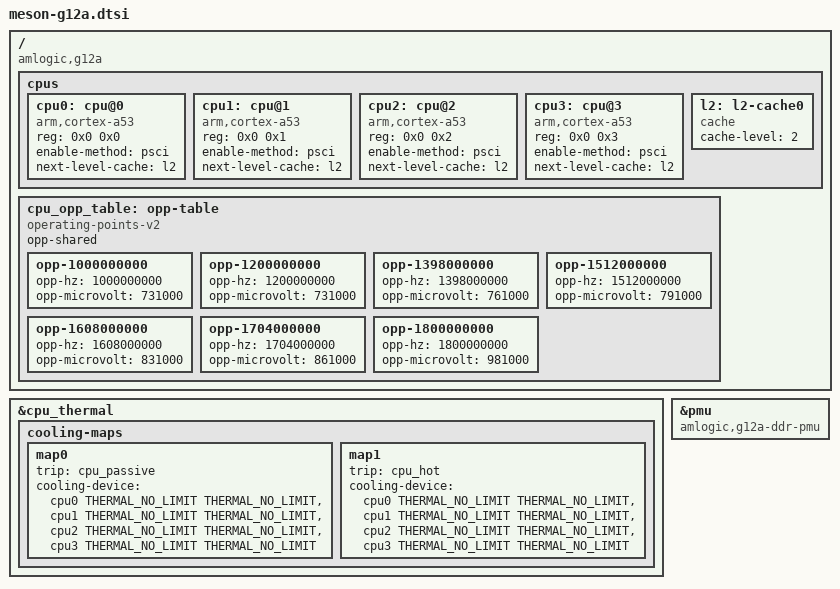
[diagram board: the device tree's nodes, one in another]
// SPDX-License-Identifier: (GPL-2.0+ OR MIT)
/*
 * Copyright (c) 2018 Amlogic, Inc. All rights reserved.
 */

#include "meson-g12.dtsi"

/ {
	compatible = "amlogic,g12a";

	cpus {
		#address-cells = <0x2>;
		#size-cells = <0x0>;

		cpu0: cpu@0 {
			device_type = "cpu";
			compatible = "arm,cortex-a53";
			reg = <0x0 0x0>;
			enable-method = "psci";
			next-level-cache = <&l2>;
			#cooling-cells = <2>;
		};

		cpu1: cpu@1 {
			device_type = "cpu";
			compatible = "arm,cortex-a53";
			reg = <0x0 0x1>;
			enable-method = "psci";
			next-level-cache = <&l2>;
			#cooling-cells = <2>;
		};

		cpu2: cpu@2 {
			device_type = "cpu";
			compatible = "arm,cortex-a53";
			reg = <0x0 0x2>;
			enable-method = "psci";
			next-level-cache = <&l2>;
			#cooling-cells = <2>;
		};

		cpu3: cpu@3 {
			device_type = "cpu";
			compatible = "arm,cortex-a53";
			reg = <0x0 0x3>;
			enable-method = "psci";
			next-level-cache = <&l2>;
			#cooling-cells = <2>;
		};

		l2: l2-cache0 {
			compatible = "cache";
			cache-level = <2>;
		};
	};

	cpu_opp_table: opp-table {
		compatible = "operating-points-v2";
		opp-shared;

		opp-1000000000 {
			opp-hz = /bits/ 64 <1000000000>;
			opp-microvolt = <731000>;
		};

		opp-1200000000 {
			opp-hz = /bits/ 64 <1200000000>;
			opp-microvolt = <731000>;
		};

		opp-1398000000 {
			opp-hz = /bits/ 64 <1398000000>;
			opp-microvolt = <761000>;
		};

		opp-1512000000 {
			opp-hz = /bits/ 64 <1512000000>;
			opp-microvolt = <791000>;
		};

		opp-1608000000 {
			opp-hz = /bits/ 64 <1608000000>;
			opp-microvolt = <831000>;
		};

		opp-1704000000 {
			opp-hz = /bits/ 64 <1704000000>;
			opp-microvolt = <861000>;
		};

		opp-1800000000 {
			opp-hz = /bits/ 64 <1800000000>;
			opp-microvolt = <981000>;
		};
	};
};

&cpu_thermal {
	cooling-maps {
		map0 {
			trip = <&cpu_passive>;
			cooling-device = <&cpu0 THERMAL_NO_LIMIT THERMAL_NO_LIMIT>,
					<&cpu1 THERMAL_NO_LIMIT THERMAL_NO_LIMIT>,
					<&cpu2 THERMAL_NO_LIMIT THERMAL_NO_LIMIT>,
					<&cpu3 THERMAL_NO_LIMIT THERMAL_NO_LIMIT>;
		};

		map1 {
			trip = <&cpu_hot>;
			cooling-device = <&cpu0 THERMAL_NO_LIMIT THERMAL_NO_LIMIT>,
					<&cpu1 THERMAL_NO_LIMIT THERMAL_NO_LIMIT>,
					<&cpu2 THERMAL_NO_LIMIT THERMAL_NO_LIMIT>,
					<&cpu3 THERMAL_NO_LIMIT THERMAL_NO_LIMIT>;
		};
	};
};

&pmu {
	compatible = "amlogic,g12a-ddr-pmu";
};
